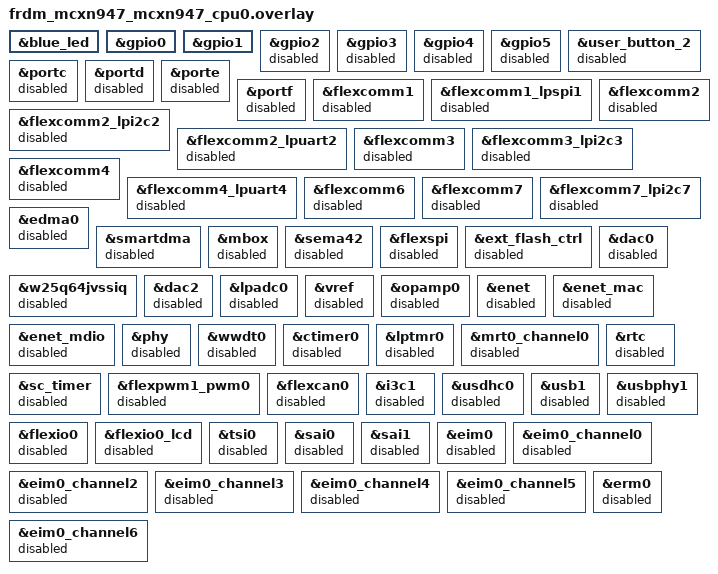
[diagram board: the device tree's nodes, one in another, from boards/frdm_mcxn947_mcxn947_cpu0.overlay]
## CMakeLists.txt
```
# SPDX-License-Identifier: Apache-2.0

# C dialect gnu17, matching ETX. Zephyr emits -std=gnu17 from
# CONFIG_STD_C17 with CONFIG_GNU_C_EXTENSIONS=y. CMAKE_C_STANDARD 17
# (extensions on by default) makes CMake append a second -std=gnu17, as on ETX.
set(CMAKE_C_STANDARD 17)

cmake_minimum_required(VERSION 3.20.0)
find_package(Zephyr REQUIRED HINTS $ENV{ZEPHYR_BASE})
project(bmt_zephyr)

# Frame buffer at 0x30030000 (RAM-E), data, bss and noinit at 0x30033000
# (RAM-E). Layout: boards/linker_layout.md.
zephyr_linker_sources(RAM_SECTIONS boards/zephyr_ram_start.ld)
# Vector table at 0x30000000, rodata at 0x30000400 (RAM-A), text at
# 0x30008000 (RAM-B).
zephyr_linker_sources(ROM_START SORT_KEY zzz boards/zephyr_rom_start.ld)

target_include_directories(app PRIVATE ${CMAKE_CURRENT_SOURCE_DIR}/src
                                      ${CMAKE_CURRENT_SOURCE_DIR}/src/task_switching
                                      ${CMAKE_CURRENT_SOURCE_DIR}/src/zephyr_api_simulation)

target_sources(app PRIVATE src/bmth_port.c)

# Zephyr API simulation: the kernel chains that cannot be timed in the kernel
# itself, re-run without a context switch.
target_sources(app PRIVATE src/zephyr_api_simulation/sim_init.c
                           src/zephyr_api_simulation/sim_sched.c)

# Exactly one benchmark test is linked in; the choice in Kconfig picks it.
# Each test directory carries its own zephyr_sim.c with the measure_*_overhead()
# probes it needs, built on the shared simulation in zephyr_api_simulation/.
target_sources_ifdef(CONFIG_BENCHMARK_TEST_TASK_SWITCHING_EVENT_PREEMPT app PRIVATE
                     src/task_switching/event_preempt/time_task_switch_event.c
                     src/task_switching/event_preempt/zephyr_sim.c)

target_sources_ifdef(CONFIG_BENCHMARK_TEST_TASK_SWITCHING_SEM_PREEMPT app PRIVATE
                     src/task_switching/sem_preempt/time_task_switch_sem.c
                     src/task_switching/sem_preempt/zephyr_sim.c)

target_sources_ifdef(CONFIG_BENCHMARK_TEST_TASK_SWITCHING_SEM_BLOCK app PRIVATE
                     src/task_switching/sem_block/time_task_switch_sem.c
                     src/task_switching/sem_block/zephyr_sim.c)

target_sources_ifdef(CONFIG_BENCHMARK_TEST_TASK_SWITCHING_EVENT_BLOCK app PRIVATE
                     src/task_switching/event_block/time_task_switch_event.c
                     src/task_switching/event_block/zephyr_sim.c)

target_sources_ifdef(CONFIG_BENCHMARK_TEST_TASK_SWITCHING_TASK_CHANGE app PRIVATE
                     src/task_switching/task_change/time_task_switch.c)

target_sources_ifdef(CONFIG_BENCHMARK_TEST_TASK_SWITCHING_TASK_PREEMPT app PRIVATE
                     src/task_switching/task_preempt/time_task_switch.c
                     src/task_switching/task_preempt/zephyr_sim.c)

target_sources_ifdef(CONFIG_BENCHMARK_TEST_IRT app PRIVATE
                     src/irt/time_interrupt_response.c)

target_sources_ifdef(CONFIG_BENCHMARK_TEST_ITC_MAILBOX_ASYNC app PRIVATE
                     src/itc/mailbox/mailbox_async.c)

target_sources_ifdef(CONFIG_BENCHMARK_TEST_ITC_FIFO app PRIVATE
                     src/itc/fifo/fifo.c)

target_sources_ifdef(CONFIG_BENCHMARK_TEST_ITC_LIFO app PRIVATE
                     src/itc/lifo/lifo.c)

target_sources_ifdef(CONFIG_BENCHMARK_TEST_ITC_STACK app PRIVATE
                     src/itc/stack/stack.c)

target_sources_ifdef(CONFIG_BENCHMARK_TEST_ITC_MSGQ app PRIVATE
                     src/itc/msgq/msgq.c)

target_sources_ifdef(CONFIG_BENCHMARK_TEST_ITC_PIPE_ASYNC app PRIVATE
                     src/itc/pipe/pipe_async.c)

target_sources_ifdef(CONFIG_BENCHMARK_TEST_ITC_MAILBOX_SYNC app PRIVATE
                     src/itc/mailbox/mailbox_sync.c)

target_sources_ifdef(CONFIG_BENCHMARK_TEST_ITC_PIPE_SYNC app PRIVATE
                     src/itc/pipe/pipe_sync.c)

target_include_directories_ifdef(CONFIG_BENCHMARK_TEST_TASK_SWITCHING_TASK_PREEMPT app PRIVATE
                                src/task_switching/task_preempt)
target_include_directories_ifdef(CONFIG_BENCHMARK_TEST_TASK_SWITCHING_TASK_CHANGE app PRIVATE
                                src/task_switching/task_change)
target_include_directories_ifdef(CONFIG_BENCHMARK_TEST_TASK_SWITCHING_EVENT_PREEMPT app PRIVATE
                           src/task_switching/event_preempt)
target_include_directories_ifdef(CONFIG_BENCHMARK_TEST_TASK_SWITCHING_EVENT_BLOCK app PRIVATE
                           src/task_switching/event_block)
target_include_directories_ifdef(CONFIG_BENCHMARK_TEST_TASK_SWITCHING_SEM_PREEMPT app PRIVATE
                           src/task_switching/sem_preempt)
target_include_directories_ifdef(CONFIG_BENCHMARK_TEST_TASK_SWITCHING_SEM_BLOCK app PRIVATE
                           src/task_switching/sem_block)
target_include_directories_ifdef(CONFIG_BENCHMARK_TEST_IRT app PRIVATE
                           src/irt)
target_include_directories_ifdef(CONFIG_BENCHMARK_TEST_ITC_MAILBOX_ASYNC app PRIVATE
                           src/itc/mailbox)
target_include_directories_ifdef(CONFIG_BENCHMARK_TEST_ITC_FIFO app PRIVATE
                           src/itc/fifo)
target_include_directories_ifdef(CONFIG_BENCHMARK_TEST_ITC_LIFO app PRIVATE
                           src/itc/lifo)
target_include_directories_ifdef(CONFIG_BENCHMARK_TEST_ITC_STACK app PRIVATE
                           src/itc/stack)
target_include_directories_ifdef(CONFIG_BENCHMARK_TEST_ITC_MSGQ app PRIVATE
                           src/itc/msgq)
target_include_directories_ifdef(CONFIG_BENCHMARK_TEST_ITC_PIPE_ASYNC app PRIVATE
                           src/itc/pipe)
target_include_directories_ifdef(CONFIG_BENCHMARK_TEST_ITC_MAILBOX_SYNC app PRIVATE
                           src/itc/mailbox)
target_include_directories_ifdef(CONFIG_BENCHMARK_TEST_ITC_PIPE_SYNC app PRIVATE
                           src/itc/pipe)

# The allocation tests. One adapter per allocator, plus the portable workload
# in mem_harness.c and the one Zephyr-aware file they share. The adapter is the
# only file that knows which allocator is under test.
target_sources_ifdef(CONFIG_BENCHMARK_TEST_MEM_SYS_HEAP app PRIVATE
                     src/mem/sys_heap/sys_heap.c
                     src/mem/mem_zephyr_main.c)

target_sources_ifdef(CONFIG_BENCHMARK_TEST_MEM_K_HEAP app PRIVATE
                     src/mem/k_heap/k_heap.c
                     src/mem/mem_zephyr_main.c)

target_sources_ifdef(CONFIG_BENCHMARK_TEST_MEM_K_MALLOC app PRIVATE
                     src/mem/k_malloc/k_malloc.c
                     src/mem/mem_zephyr_main.c)

target_sources_ifdef(CONFIG_BENCHMARK_TEST_MEM_SLAB app PRIVATE
                     src/mem/mem_slab/mem_slab.c
                     src/mem/mem_zephyr_main.c)

target_sources_ifdef(CONFIG_BENCHMARK_TEST_MEM_BLOCKS app PRIVATE
                     src/mem/mem_blocks/mem_blocks.c
                     src/mem/mem_zephyr_main.c)

# mem_allocator.h and mem_harness.h are shared by all five: one workload, one
# measurement window, so the numbers compare.
target_include_directories_ifdef(CONFIG_BENCHMARK_TEST_MEM_SYS_HEAP app PRIVATE
                                src/mem)
target_include_directories_ifdef(CONFIG_BENCHMARK_TEST_MEM_K_HEAP app PRIVATE
                                src/mem)
target_include_directories_ifdef(CONFIG_BENCHMARK_TEST_MEM_K_MALLOC app PRIVATE
                                src/mem)
target_include_directories_ifdef(CONFIG_BENCHMARK_TEST_MEM_SLAB app PRIVATE
                                src/mem)
target_include_directories_ifdef(CONFIG_BENCHMARK_TEST_MEM_BLOCKS app PRIVATE
                                src/mem)

# src/mem/mem_zephyr_heap.h reads the heap's own chunk walk to report the
# total used space and the fixed arena cost, which needs lib/heap/heap.h. That
# header is private to the kernel and is not on the default include path. Only
# the three heap cases include it; the slab and the blocks cases read their own
# allocator's state and must not gain the path.
target_include_directories_ifdef(CONFIG_BENCHMARK_TEST_MEM_SYS_HEAP app PRIVATE
                                ${ZEPHYR_BASE}/lib/heap)
target_include_directories_ifdef(CONFIG_BENCHMARK_TEST_MEM_K_HEAP app PRIVATE
                                ${ZEPHYR_BASE}/lib/heap)
target_include_directories_ifdef(CONFIG_BENCHMARK_TEST_MEM_K_MALLOC app PRIVATE
                                ${ZEPHYR_BASE}/lib/heap)

# HMS benchmark package
set(benchmark_path ${CMAKE_CURRENT_SOURCE_DIR}/packages/benchmark_hms)
include(${benchmark_path}/CMakeLists.txt)

target_link_libraries(app PRIVATE bmth)
```

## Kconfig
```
#
# SPDX-License-Identifier: BSD-3-Clause
# Copyright (c) 2026 HMS Industrial Networks GmbH & Co. KG
# Author: Isaac L. L. Yuki
#

choice BENCHMARK_TEST
    prompt "Benchmark test to build"
    default BENCHMARK_TEST_TASK_SWITCHING_EVENT_PREEMPT
    help
      Exactly one benchmark test builds into the image.

config BENCHMARK_TEST_TASK_SWITCHING_EVENT_PREEMPT
    bool "Task switch via k_event, preempting waiter"
    help
      src/task_switching/event_preempt/time_task_switch_event.c

config BENCHMARK_TEST_TASK_SWITCHING_EVENT_BLOCK
    bool "Task switch via k_event, blocking waiter"
    help
      src/task_switching/event_block/time_task_switch_event.c

config BENCHMARK_TEST_TASK_SWITCHING_TASK_CHANGE
    bool "Task switch via k_yield()"
    help
      src/task_switching/task_change/time_task_switch.c

config BENCHMARK_TEST_TASK_SWITCHING_TASK_PREEMPT
    bool "Task switch via k_thread_resume()"
    help
      src/task_switching/task_preempt/time_task_switch.c

config BENCHMARK_TEST_TASK_SWITCHING_SEM_PREEMPT
    bool "Task switch via k_sem, preempting waiter"
    help
      src/task_switching/sem_preempt/time_task_switch_sem.c

config BENCHMARK_TEST_TASK_SWITCHING_SEM_BLOCK
    bool "Task switch via k_sem, blocking waiter"
    help
      src/task_switching/sem_block/time_task_switch_sem.c

config BENCHMARK_TEST_IRT
    bool "Interrupt latency via a self-induced interrupt"
    help
      src/irt/time_interrupt_response.c

config BENCHMARK_TEST_ITC_MAILBOX_ASYNC
    bool "Message passing via k_mbox, asynchronous"
    help
      src/itc/mailbox/mailbox_async.c

config BENCHMARK_TEST_ITC_FIFO
    bool "Message passing via k_fifo"
    help
      src/itc/fifo/fifo.c

config BENCHMARK_TEST_ITC_LIFO
    bool "Message passing via k_lifo"
    help
      src/itc/lifo/lifo.c

config BENCHMARK_TEST_ITC_STACK
    bool "Message passing via k_stack"
    help
      src/itc/stack/stack.c

config BENCHMARK_TEST_ITC_MSGQ
    bool "Message passing via k_msgq"
    help
      src/itc/msgq/msgq.c

config BENCHMARK_TEST_ITC_PIPE_ASYNC
    bool "Message passing via k_pipe, buffered"
    help
      src/itc/pipe/pipe_async.c

config BENCHMARK_TEST_ITC_MAILBOX_SYNC
    bool "Message passing via k_mbox, synchronous"
    help
      src/itc/mailbox/mailbox_sync.c

config BENCHMARK_TEST_ITC_PIPE_SYNC
    bool "Message passing via k_pipe, bufferless"
    help
      src/itc/pipe/pipe_sync.c

config BENCHMARK_TEST_MEM_SYS_HEAP
    select BMTH_TEST_MEM_ALLOC
    bool "Allocation via sys_heap"
    help
      src/mem/sys_heap/sys_heap.c, see src/mem/sys_heap/README.md.

config BENCHMARK_TEST_MEM_K_HEAP
    select BMTH_TEST_MEM_ALLOC
    bool "Allocation via k_heap"
    help
      src/mem/k_heap/k_heap.c, see src/mem/k_heap/README.md.

config BENCHMARK_TEST_MEM_K_MALLOC
    select BMTH_TEST_MEM_ALLOC
    bool "Allocation via k_malloc"
    help
      src/mem/k_malloc/k_malloc.c, see src/mem/k_malloc/README.md.

config BENCHMARK_TEST_MEM_SLAB
    select BMTH_TEST_MEM_ALLOC
    bool "Allocation via k_mem_slab"
    help
      src/mem/mem_slab/mem_slab.c, see src/mem/mem_slab/README.md.

config BENCHMARK_TEST_MEM_BLOCKS
    select BMTH_TEST_MEM_ALLOC
    select SYS_MEM_BLOCKS
    bool "Allocation via sys_mem_blocks"
    select SYS_MEM_BLOCKS
    help
      src/mem/mem_blocks/mem_blocks.c, see src/mem/mem_blocks/README.md.

endchoice

source "Kconfig.zephyr"
rsource "packages/benchmark_hms/Kconfig"
```

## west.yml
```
#
# SPDX-License-Identifier: BSD-3-Clause
# Copyright (c) 2026 HMS Industrial Networks GmbH & Co. KG
# Author: Isaac L. L. Yuki
#

manifest:
  remotes:
    - name: zephyrproject-rtos
      url-base: https://github.com/zephyrproject-rtos
    - name: benchmark_hms
      url-base: https://github.com/hms-isyu/

  projects:
    - name: zephyr
      remote: zephyrproject-rtos
      revision: v4.4.1 # matches on-disk cache at ThirdParty/zephyrproject/zephyr
      import: true
      path: zephyr
    - name: benchmark_test_hms
      remote: benchmark_hms
      revision: main
      path: zephyr_benchmark/packages/benchmark_hms

  self:
    path: zephyr_benchmark
```

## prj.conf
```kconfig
# Peripherals
CONFIG_GPIO=y
CONFIG_UART_CONSOLE=n
CONFIG_UART_MCUX_LPUART=n
CONFIG_UART_INTERRUPT_DRIVEN=n
CONFIG_CONSOLE=n
CONFIG_SERIAL=n
CONFIG_BT=n

# Core hardware
CONFIG_FPU=n
CONFIG_ARM_MPU=n
CONFIG_CACHE=n

# Execution
CONFIG_HW_STACK_PROTECTION=n
CONFIG_TRUSTED_EXECUTION_SECURE=n
CONFIG_XIP=n
CONFIG_MP_MAX_NUM_CPUS=1
CONFIG_FORCE_NO_ASSERT=y

# Code and algorithm
CONFIG_DEBUG=n

# Kernel
CONFIG_TIMESLICING=n
CONFIG_TICKLESS_KERNEL=y
CONFIG_SYS_CLOCK_TICKS_PER_SEC=100
CONFIG_EVENTS=y
CONFIG_NUM_PREEMPT_PRIORITIES=16
CONFIG_SCHED_MULTIQ=n
CONFIG_HEAP_MEM_POOL_SIZE=8192

# Compiler and library
CONFIG_NEWLIB_LIBC=y
CONFIG_NEWLIB_LIBC_NANO=y
CONFIG_DEBUG_OPTIMIZATIONS=y
CONFIG_STD_C17=y
CONFIG_GNU_C_EXTENSIONS=y

# Benchmark
CONFIG_BMTH_ENABLE=y
CONFIG_BMTH_FRDM_MCXN947=y
```

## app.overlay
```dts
/ {
	/*
	 * Replaced wholesale instead of property by property: the board points
	 * zephyr,console / shell-uart / uart-mcumgr at LPUART4, zephyr,canbus at
	 * flexcan0 and zephyr,code-partition at internal flash, none of which
	 * exist in this build.
	 *
	 * The led0/led1/led2 aliases come from the board dtsi already, so there is
	 * deliberately no /aliases override here.
	 */

	chosen {
		zephyr,sram = &sram0;
		zephyr,flash = &sramx;
	};
};

/* Memory configuration */

/*
 * Frame buffer, same range as BUFFERS_RAM_E in the ETX build (RAM_E_START
 * 0x30030000, FRAME_BUFFER_LENGTH 12 KB; the sram ranges map child 0x20000000
 * to 0x30000000). Becomes the NOLOAD linker region and output section
 * BUFFERS_RAM_E; boards/zephyr_ram_start.ld reserves the same window inside RAM.
 */
&sram {
	frame_buf: memory@20030000 {
		compatible = "zephyr,memory-region", "mmio-sram";
		reg = <0x20030000 0x3000>;
		zephyr,memory-region = "BUFFERS_RAM_E";
	};
};

/* Code is linked into System Bus (CONFIG_XIP=n), so the MPU must treat it as flash. */
&sramx {
	zephyr,memory-attr = <DT_MEM_ARM(ATTR_MPU_FLASH)>;
};
```

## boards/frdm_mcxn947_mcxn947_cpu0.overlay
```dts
/*
 * Minimal devicetree for the ETX/Zephyr benchmark on FRDM-MCXN947 (cpu0).
 *
 * Everything the board enables by default is switched off (besides leds) so no extra
 * driver init, peripheral clock or interrupt source can perturb a measurement.
 */

/ {
    /*
     * Replaced wholesale instead of property by property: the board points
     * zephyr,console / shell-uart / uart-mcumgr at LPUART4, zephyr,canbus at
     * flexcan0 and zephyr,code-partition at internal flash, none of which
     * exist in this build.
     *
     * The led0/led1/led2 aliases come from the board dtsi already, so there is
     * deliberately no /aliases override here.
     */
    /delete-node/ chosen;
};

/* LEDs - the only hardware the benchmark drives */

/*
 * red_led and green_led are enabled by the board already; blue_led is left
 * disabled there because P1_2 is also Arduino D6.
 *
 * No pinctrl group is needed for plain GPIO: the MCX GPIO driver rewrites each
 * pad's mux to FUNC0/GPIO in gpio_pin_configure(), so it takes the pad
 * regardless of any peripheral's default pinmux.
 */
&blue_led {
    status = "okay";
};

/*
 * GPIO ports carrying an LED. Kept explicit: disabling gpio0 is what broke the
 * previous build ('__device_dts_ord_19' undeclared), since both the red and the
 * green LED hang off it.
 */
&gpio0 {
    status = "okay";
};

&gpio1 {
    status = "okay";
};

/* Unused GPIO ports (Arduino, MikroBus and SD-card headers). */
&gpio2 {
    status = "disabled";
};

&gpio3 {
    status = "disabled";
};

&gpio4 {
    status = "disabled";
};

&gpio5 {
    status = "disabled";
};

&user_button_2 {
    status = "disabled";
};

/*
 * PORT pinmux blocks. Each gpio node points at one via nxp,kinetis-port, so
 * porta (gpio0) and portb (gpio1) must stay; the rest only existed for the
 * ports disabled above.
 */
&portc {
    status = "disabled";
};

&portd {
    status = "disabled";
};

&porte {
    status = "disabled";
};

&portf {
    status = "disabled";
};

/* LPFLEXCOMM instances - no serial console (CONFIG_SERIAL=n), no I2C, no SPI */

&flexcomm1 {
    status = "disabled";
};

&flexcomm1_lpspi1 {
    status = "disabled";
};

&flexcomm2 {
    status = "disabled";
};

&flexcomm2_lpi2c2 {
    status = "disabled";
};

&flexcomm2_lpuart2 {
    status = "disabled";
};

&flexcomm3 {
    status = "disabled";
};

&flexcomm3_lpi2c3 {
    status = "disabled";
};

&flexcomm4 {
    status = "disabled";
};

&flexcomm4_lpuart4 {
    status = "disabled";
};

&flexcomm6 {
    status = "disabled";
};

&flexcomm7 {
    status = "disabled";
};

&flexcomm7_lpi2c7 {
    status = "disabled";
};

/* DMA, mailbox and inter-core */

&edma0 {
    status = "disabled";
};

&smartdma {
    status = "disabled";
};

&mbox {
    status = "disabled";
};

&sema42 {
    status = "disabled";
};

/* External QSPI flash */

&flexspi {
    status = "disabled";
};

&ext_flash_ctrl {
    status = "disabled";
};

&w25q64jvssiq {
    status = "disabled";
};

/* Analog */

&dac0 {
    status = "disabled";
};

&dac2 {
    status = "disabled";
};

&lpadc0 {
    status = "disabled";
};

&vref {
    status = "disabled";
};

&opamp0 {
    status = "disabled";
};

/* Ethernet */

&enet {
    status = "disabled";
};

&enet_mac {
    status = "disabled";
};

&enet_mdio {
    status = "disabled";
};

&phy {
    status = "disabled";
};

/* Timers and counters other than the kernel's SysTick */

&wwdt0 {
    status = "disabled";
};

&ctimer0 {
    status = "disabled";
};

&lptmr0 {
    status = "disabled";
};

&mrt0_channel0 {
    status = "disabled";
};

&rtc {
    status = "disabled";
};

&sc_timer {
    status = "disabled";
};

&flexpwm1_pwm0 {
    status = "disabled";
};

/* Buses and interfaces */

&flexcan0 {
    status = "disabled";
};

&i3c1 {
    status = "disabled";
};

&usdhc0 {
    status = "disabled";
};

&usb1 {
    status = "disabled";
};

&usbphy1 {
    status = "disabled";
};

/*
 * FlexIO. J8 is the FlexIO/LCD header; disabling flexio0_lcd releases those
 * pads (it only actually claims them with the LCD shield present, but keep it
 * explicit).
 */
&flexio0 {
    status = "disabled";
};

&flexio0_lcd {
    status = "disabled";
};

/* Touch */

&tsi0 {
    status = "disabled";
};

/* Audio */

&sai0 {
    status = "disabled";
};

&sai1 {
    status = "disabled";
};

/* Memory error injection and reporting (the board enables these by default) */

&eim0 {
    status = "disabled";
};

&eim0_channel0 {
    status = "disabled";
};

&eim0_channel2 {
    status = "disabled";
};

&eim0_channel3 {
    status = "disabled";
};

&eim0_channel4 {
    status = "disabled";
};

&eim0_channel5 {
    status = "disabled";
};

&eim0_channel6 {
    status = "disabled";
};

&erm0 {
    status = "disabled";
};
```

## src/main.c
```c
/*
 * Copyright (c) 2016 Intel Corporation
 *
 * SPDX-License-Identifier: Apache-2.0
 */

#include <stdio.h>
#include <zephyr/kernel.h>
#include <zephyr/drivers/gpio.h>

/* 1000 msec = 1 sec */
#define SLEEP_TIME_MS   500

/* The devicetree node identifier for the "led0" alias. */
#define LED0_NODE DT_ALIAS(led1)

/* out7 -> J8 physical pin 28 (FlexIO LCD_D15, gpio4 23). */
#define OUT7_NODE DT_NODELABEL(out7)

/*
 * A build error on this line means your board is unsupported.
 * See the sample documentation for information on how to fix this.
 */
static const struct gpio_dt_spec led = GPIO_DT_SPEC_GET(LED0_NODE, gpios);
static const struct gpio_dt_spec out7 = GPIO_DT_SPEC_GET(OUT7_NODE, gpios);

/* LED toggling task */
#define LED_THREAD_STACK_SIZE 512
#define LED_THREAD_PRIORITY   5

K_THREAD_STACK_DEFINE(led_stack, LED_THREAD_STACK_SIZE);
static struct k_thread led_thread_data;

static void led_task(void *p1, void *p2, void *p3)
{
	int ret;
	bool led_state = true;

	ARG_UNUSED(p1);
	ARG_UNUSED(p2);
	ARG_UNUSED(p3);

	while (1) {
		ret = gpio_pin_toggle_dt(&led);
		if (ret < 0) {
			return;
		}

		led_state = !led_state;
		printf("LED state: %s\n", led_state ? "ON" : "OFF");
		k_msleep(SLEEP_TIME_MS);
	}
}

int main(void)
{
	int ret;

	if (!gpio_is_ready_dt(&led)) {
		return 0;
	}

	ret = gpio_pin_configure_dt(&led, GPIO_OUTPUT_ACTIVE);
	if (ret < 0) {
		return 0;
	}

	/* Drive J8 pin 28 HIGH. out7 is GPIO_ACTIVE_HIGH, so OUTPUT_ACTIVE = high. */
	if (!gpio_is_ready_dt(&out7)) {
		printf("Something went wrong!");
		return 0;
	}

	ret = gpio_pin_configure_dt(&out7, GPIO_OUTPUT_ACTIVE);
	if (ret < 0) {
		return 0;
	}

	/* GPIO is configured; start the LED toggling task. */
	k_thread_create(&led_thread_data, led_stack, LED_THREAD_STACK_SIZE,
			led_task, NULL, NULL, NULL,
			LED_THREAD_PRIORITY, 0, K_NO_WAIT);

	return 0;
}
```

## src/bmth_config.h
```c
/******************************************************************************/
/*!
 * \copyright
 * SPDX-License-Identifier: BSD-3-Clause
 * Copyright (c) 2026 HMS Industrial Networks GmbH & Co. KG
 * \author Isaac L. L. Yuki
 */
/******************************************************************************/

/*!
 * \ingroup BMT_HMS
 * \brief Port layer for the benchmark.
 * @{
 * \file
 */

#ifndef BMTH_CONFIG_H
#define BMTH_CONFIG_H

/*******************************************************************************
 * Includes
 ******************************************************************************/

#include "cmsis_core.h"

#ifdef __ZEPHYR__
#include <zephyr/devicetree.h>
#include <zephyr/linker/devicetree_regions.h>
#include <zephyr/toolchain.h>
#endif /* __ZEPHYR__ */

/*******************************************************************************
 * Definitions
 ******************************************************************************/

#define BMTH_COUNTER_FREQUENCY (SystemCoreClock) /* in MHz */

#ifdef __CORTEX_M
#define BMTH_GET_COUNTER() DWT->CYCCNT
#define BMTH_RESET_COUNTER() DWT->CYCCNT = 0U
#define BMTH_GET_TIMER() DWT->CYCCNT
#define BMTH_RESET_TIMER() DWT->CYCCNT = 0U
#endif /* __CORTEX_M */

#define BMTH_SIGNALING_EVNT_DURATION (1000U)

#define BMTH_GLOBAL_TIME_STORAGE                                               \
  (0U) /* 1: store global time, 0: do not store global time */

/** @brief Minimum step size exponent. */
#define BMTH_MEM_S_MIN (3U)

/** @brief Maximum step size exponent. */
#define BMTH_MEM_S_MAX (10U)

#define BMTH_MEM_ARENA_MULTIPLIER (8U)

#ifdef __ZEPHYR__
/** @brief Devicetree node that provides the BUFFERS_RAM_E region. */
#define BMTH_BUFFER_NODE DT_NODELABEL(frame_buf)

#if DT_NODE_HAS_PROP(BMTH_BUFFER_NODE, zephyr_memory_region)
/** @brief Places a test buffer in the BUFFERS_RAM_E output section. */
#define BMTH_BUFFER_SECTION                                                    \
  Z_GENERIC_SECTION(LINKER_DT_NODE_REGION_NAME_TOKEN(BMTH_BUFFER_NODE))
#else
#error "No frame_buf node with zephyr,memory-region (BUFFERS_RAM_E)"
#endif
#endif /* __ZEPHYR__ */

#endif /* BMTH_CONFIG_H */

/*!@}*/
```

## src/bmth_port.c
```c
/******************************************************************************/
/*!
 * \copyright
 * SPDX-License-Identifier: BSD-3-Clause
 * Copyright (c) 2026 HMS Industrial Networks GmbH & Co. KG
 * \author Isaac L. L. Yuki
 */
/******************************************************************************/

/*!
 * \ingroup BMT_HMS
 * \brief Port layer for the benchmark.
 * @{
 * \file
 */

/*******************************************************************************
 * Includes
 ******************************************************************************/

#include <zephyr/kernel.h>
#include <zephyr/drivers/gpio.h>

#include "benchmark_tools_hms.h"

/*******************************************************************************
 * Variables
 ******************************************************************************/

static const struct gpio_dt_spec led0 = GPIO_DT_SPEC_GET(DT_ALIAS(led0), gpios);
static const struct gpio_dt_spec led1 = GPIO_DT_SPEC_GET(DT_ALIAS(led1), gpios);
static const struct gpio_dt_spec led2 = GPIO_DT_SPEC_GET(DT_ALIAS(led2), gpios);

/*******************************************************************************
 * Code
 ******************************************************************************/

void BMTH_hardware_init(bool quiet)
{
  if (quiet)
  {
    BMTH_disable_noise_sources();
  }

  /*done by board early init hook just check*/

  BMTH_ASSERT(gpio_is_ready_dt(&led0));
  BMTH_ASSERT(gpio_is_ready_dt(&led1));
  BMTH_ASSERT(gpio_is_ready_dt(&led2));
  int ret = gpio_pin_configure_dt(&led0, GPIO_OUTPUT_INACTIVE);
  BMTH_ASSERT(ret == 0);
  ret = gpio_pin_configure_dt(&led1, GPIO_OUTPUT_INACTIVE);
  BMTH_ASSERT(ret == 0);
  ret = gpio_pin_configure_dt(&led2, GPIO_OUTPUT_INACTIVE);
  BMTH_ASSERT(ret == 0);
}

void BMTH_toggle_signal_success(void)
{
  gpio_pin_toggle_dt(&led1);
}

void BMTH_toggle_signal_failure(void)
{
  gpio_pin_toggle_dt(&led0);
}

void BMTH_toggle_signal_event(void)
{
  gpio_pin_toggle_dt(&led2);
}

/*!@}*/
```
